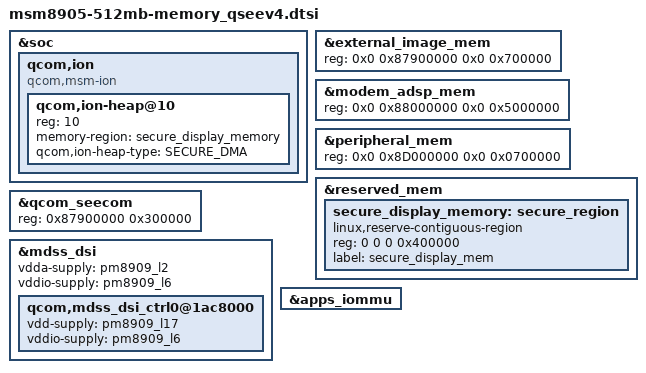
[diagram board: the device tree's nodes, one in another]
/*
 * Copyright (c) 2017, 2020, The Linux Foundation. All rights reserved.
 *
 * This program is free software; you can redistribute it and/or modify
 * it under the terms of the GNU General Public License version 2 and
 * only version 2 as published by the Free Software Foundation.
 *
 * This program is distributed in the hope that it will be useful,
 * but WITHOUT ANY WARRANTY; without even the implied warranty of
 * MERCHANTABILITY or FITNESS FOR A PARTICULAR PURPOSE.  See the
 * GNU General Public License for more details.
 */

&soc {
	qcom,ion {
		compatible = "qcom,msm-ion";
		#address-cells = <1>;
		#size-cells = <0>;

			qcom,ion-heap@10 { /* SECURE DISPLAY HEAP */
				reg = <10>;
				memory-region = <&secure_display_memory>;
				qcom,ion-heap-type = "SECURE_DMA";
			};
	};
};

&external_image_mem {
	reg = <0x0 0x87900000 0x0 0x700000>;
};

&modem_adsp_mem {
	reg = <0x0 0x88000000 0x0 0x5000000>;
};

&peripheral_mem {
	reg = <0x0 0x8D000000 0x0 0x0700000>;
};

&reserved_mem {
	secure_display_memory: secure_region {
		linux,reserve-contiguous-region;
		reg = <0 0 0 0x400000>;
		label = "secure_display_mem";
	};
};

&qcom_seecom {
	reg = <0x87900000 0x300000>;
};

&mdss_dsi {
	vdda-supply = <&pm8909_l2>;
	vddio-supply = <&pm8909_l6>;
	qcom,mdss_dsi_ctrl0@1ac8000 {
		vdd-supply = <&pm8909_l17>;
		vddio-supply = <&pm8909_l6>;
	};
};

&apps_iommu {
	status = "okay";
};
